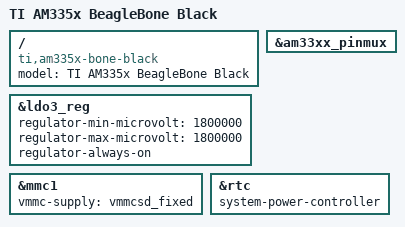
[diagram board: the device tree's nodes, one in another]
/*
 * Copyright (C) 2012 Texas Instruments Incorporated - http://www.ti.com/
 *
 * This program is free software; you can redistribute it and/or modify
 * it under the terms of the GNU General Public License version 2 as
 * published by the Free Software Foundation.
 */
/dts-v1/;

#include "am33xx.dtsi"
#include "am335x-bone-common-no-capemgr.dtsi"

/ {
	model = "TI AM335x BeagleBone Black";
	compatible = "ti,am335x-bone-black", "ti,am335x-bone", "ti,am33xx";
};

/* Max Core Speed */
#include "am335x-boneblack-1ghz.dtsi"
/* #include "am335x-boneblack-800mhz.dtsi" */

&ldo3_reg {
	regulator-min-microvolt = <1800000>;
	regulator-max-microvolt = <1800000>;
	regulator-always-on;
};

&mmc1 {
	vmmc-supply = <&vmmcsd_fixed>;
};

&am33xx_pinmux {
	pinctrl-names = "default";
	/* pinctrl-0 = <&clkout2_pin>; */
};

#include "am335x-peripheral-emmc.dtsi"
#include "am335x-bone-pinmux-emmc.dtsi"
/* #include "am335x-bone-emmc-in-reset.dtsi" */

#include "am335x-peripheral-nxp-hdmi.dtsi"
#include "am335x-bone-pinmux-nxp-hdmi.dtsi"

&rtc {
	system-power-controller;
};

#include "am335x-bone-argus.dtsi"
